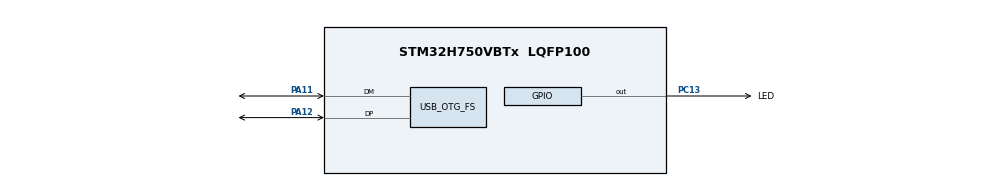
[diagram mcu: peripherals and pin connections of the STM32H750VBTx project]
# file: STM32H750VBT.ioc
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Mcu.Family=STM32H7
Mcu.Name=STM32H750VBTx
Mcu.Package=LQFP100
NVIC.OTG_FS_IRQn=true\:0\:0\:false\:false\:true\:false\:true
NVIC.PriorityGroup=NVIC_PRIORITYGROUP_4
PA11.Mode=Device_Only
PA11.Signal=USB_OTG_FS_DM
PA12.Mode=Device_Only
PA12.Signal=USB_OTG_FS_DP
PA13\ (JTMS/SWDIO).Mode=Serial_Wire
PA13\ (JTMS/SWDIO).Signal=DEBUG_JTMS-SWDIO
PA14\ (JTCK/SWCLK).Mode=Serial_Wire
PA14\ (JTCK/SWCLK).Signal=DEBUG_JTCK-SWCLK
PC13.GPIO_Label=LED
PC13.Signal=GPIO_Output
PC14-OSC32_IN\ (OSC32_IN).Mode=LSE-External-Oscillator
PC14-OSC32_IN\ (OSC32_IN).Signal=RCC_OSC32_IN
PC15-OSC32_OUT\ (OSC32_OUT).Mode=LSE-External-Oscillator
PC15-OSC32_OUT\ (OSC32_OUT).Signal=RCC_OSC32_OUT
PH0-OSC_IN\ (PH0).Mode=HSE-External-Oscillator
PH0-OSC_IN\ (PH0).Signal=RCC_OSC_IN
PH1-OSC_OUT\ (PH1).Mode=HSE-External-Oscillator
PH1-OSC_OUT\ (PH1).Signal=RCC_OSC_OUT
ProjectManager.HeapSize=0x1600
ProjectManager.StackSize=0x1600
ProjectManager.TargetToolchain=MDK-ARM V5.32
RCC.ADCFreq_Value=50390625
RCC.APB1Freq_Value=100000000
RCC.APB2Freq_Value=100000000
RCC.APB3Freq_Value=100000000
RCC.APB4Freq_Value=100000000
RCC.CortexFreq_Value=200000000
RCC.DIVM1=2
RCC.DIVN1=32
RCC.DIVQ1=7
RCC.HCLKFreq_Value=100000000
RCC.HPRE=RCC_HCLK_DIV2
RCC.PLL1_VCI_Range=RCC_PLL1VCIRANGE_3
RCC.PLL2FRACN=0
RCC.PLL3FRACN=0
RCC.PLLFRACN=0
RCC.PLLSourceVirtual=RCC_PLLSOURCE_HSE
RCC.PWR_Regulator_Voltage_Scale=PWR_REGULATOR_VOLTAGE_SCALE3
RCC.SYSCLKFreq_VALUE=200000000
RCC.SYSCLKSource=RCC_SYSCLKSOURCE_PLLCLK
RCC.USBCLockSelection=RCC_USBCLKSOURCE_HSI48
RCC.USBFreq_Value=48000000
USB_DEVICE.CLASS_NAME_FS=CDC
USB_DEVICE.VirtualMode-CDC_FS=Cdc
USB_DEVICE.VirtualModeFS=Cdc_FS
USB_OTG_FS.VirtualMode=Device_Only
VP_USB_DEVICE_VS_USB_DEVICE_CDC_FS.Mode=CDC_FS
board=custom

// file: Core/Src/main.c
/* USER CODE BEGIN Header */
/**
  ******************************************************************************
  * @file           : main.c
  * @brief          : Main program body
  ******************************************************************************
  * @attention
  *
  * Copyright (c) 2021 STMicroelectronics.
  * All rights reserved.
  *
  * This software is licensed under terms that can be found in the LICENSE file
  * in the root directory of this software component.
  * If no LICENSE file comes with this software, it is provided AS-IS.
  *
  ******************************************************************************
  */
/* USER CODE END Header */
#include "main.h"
#include "usb_device.h"
#include "gpio.h"

void SystemClock_Config(void);

int main(void)
{

  /* MCU Configuration--------------------------------------------------------*/

  /* Reset of all peripherals, Initializes the Flash interface and the Systick. */
  HAL_Init();

  /* Configure the system clock */
  SystemClock_Config();

  /* Initialize all configured peripherals */
  MX_GPIO_Init();
  MX_USB_DEVICE_Init();

  /* Infinite loop */
  while (1)
  {

    /* USER CODE BEGIN 3 */
		HAL_Delay(2000);
		HAL_GPIO_TogglePin(LED_GPIO_Port, LED_Pin);
  }
  /* USER CODE END 3 */
}

void SystemClock_Config(void)
{
  RCC_OscInitTypeDef RCC_OscInitStruct = {0};
  RCC_ClkInitTypeDef RCC_ClkInitStruct = {0};

  /** Supply configuration update enable
  */
  HAL_PWREx_ConfigSupply(PWR_LDO_SUPPLY);
  /** Configure the main internal regulator output voltage
  */
  __HAL_PWR_VOLTAGESCALING_CONFIG(PWR_REGULATOR_VOLTAGE_SCALE3);

  while(!__HAL_PWR_GET_FLAG(PWR_FLAG_VOSRDY)) {}
  /** Initializes the RCC Oscillators according to the specified parameters
  * in the RCC_OscInitTypeDef structure.
  */
  RCC_OscInitStruct.OscillatorType = RCC_OSCILLATORTYPE_HSI48|RCC_OSCILLATORTYPE_HSE;
  RCC_OscInitStruct.HSEState = RCC_HSE_ON;
  RCC_OscInitStruct.HSI48State = RCC_HSI48_ON;
  RCC_OscInitStruct.PLL.PLLState = RCC_PLL_ON;
  RCC_OscInitStruct.PLL.PLLSource = RCC_PLLSOURCE_HSE;
  RCC_OscInitStruct.PLL.PLLM = 2;
  RCC_OscInitStruct.PLL.PLLN = 32;
  RCC_OscInitStruct.PLL.PLLP = 2;
  RCC_OscInitStruct.PLL.PLLQ = 7;
  RCC_OscInitStruct.PLL.PLLR = 2;
  RCC_OscInitStruct.PLL.PLLRGE = RCC_PLL1VCIRANGE_3;
  RCC_OscInitStruct.PLL.PLLVCOSEL = RCC_PLL1VCOWIDE;
  RCC_OscInitStruct.PLL.PLLFRACN = 0;
  if (HAL_RCC_OscConfig(&RCC_OscInitStruct) != HAL_OK)
  {
    Error_Handler();
  }
  /** Initializes the CPU, AHB and APB buses clocks
  */
  RCC_ClkInitStruct.ClockType = RCC_CLOCKTYPE_HCLK|RCC_CLOCKTYPE_SYSCLK
                              |RCC_CLOCKTYPE_PCLK1|RCC_CLOCKTYPE_PCLK2
                              |RCC_CLOCKTYPE_D3PCLK1|RCC_CLOCKTYPE_D1PCLK1;
  RCC_ClkInitStruct.SYSCLKSource = RCC_SYSCLKSOURCE_PLLCLK;
  RCC_ClkInitStruct.SYSCLKDivider = RCC_SYSCLK_DIV1;
  RCC_ClkInitStruct.AHBCLKDivider = RCC_HCLK_DIV2;
  RCC_ClkInitStruct.APB3CLKDivider = RCC_APB3_DIV1;
  RCC_ClkInitStruct.APB1CLKDivider = RCC_APB1_DIV1;
  RCC_ClkInitStruct.APB2CLKDivider = RCC_APB2_DIV1;
  RCC_ClkInitStruct.APB4CLKDivider = RCC_APB4_DIV1;

  if (HAL_RCC_ClockConfig(&RCC_ClkInitStruct, FLASH_LATENCY_2) != HAL_OK)
  {
    Error_Handler();
  }
}

void Error_Handler(void)
{
  __disable_irq();
  while (1)
  {
  }
}
